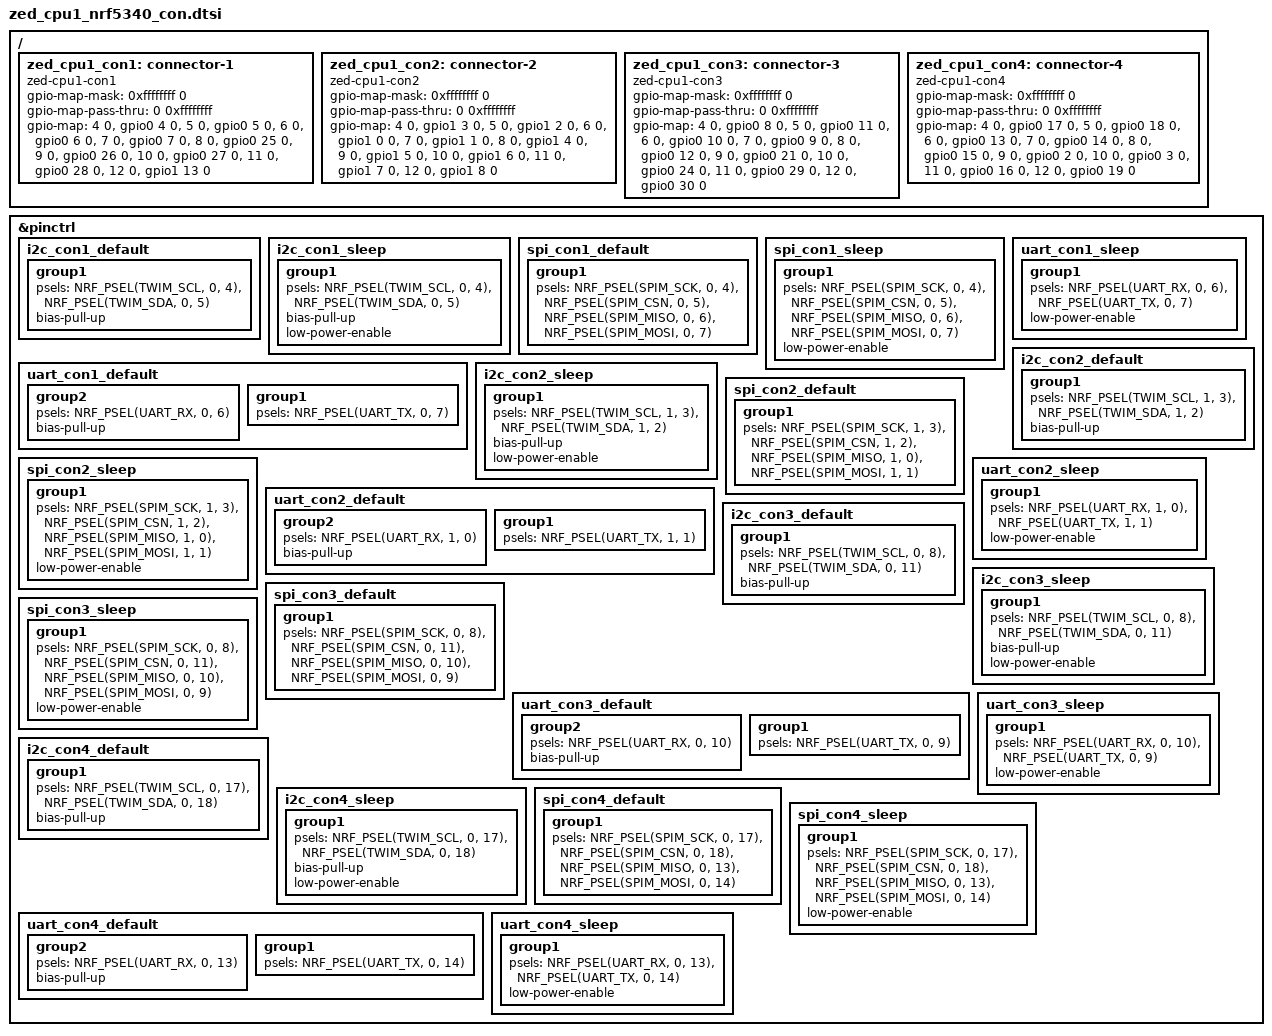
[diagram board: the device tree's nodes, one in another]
/*
 * Copyright (c) 2025 Lawrence King <lawrencek52@gmail.com>
 *
 * SPDX-License-Identifier: Apache-2.0
 */
/* TODO - add SPI to Con1 and con4 */
/*
 * the nrf5340 has many gpio pins, any of the pins on the connectors
 * can be used as GPIO, functions like I2C and PWM can be assigned
 * to any gpio. additionally the nrf5340 has some pins with special
 * features like QSPI, or ADC. These pins are located on the connectors
 * as shown below.
 */
/ {
	zed_cpu1_con1: connector-1 {
		compatible = "zed-cpu1-con1";
		#gpio-cells = <2>;
		gpio-map-mask = <0xffffffff 0>;
		gpio-map-pass-thru = <0 0xffffffff>;
		/* the connector has 12 pins,
			pin1 GND
			pin2 +3.3V
			pin3 Houskeeping ADC0
		  the remaining pins are connected to the nrf5340 */
		gpio-map = <4 0 &gpio0 4 0>,	/* SCL, AIN0, SPI_CLK P0.04 */
			   <5 0 &gpio0 5 0>,	/* SDA, AIN1, SPI_CS P0.05 */
			   <6 0 &gpio0 6 0>,	/* RXD, AIN2, SPI_MISO P0.06 */
			   <7 0 &gpio0 7 0>,	/* TXD, AIN3, SPI_MOSI P0.07 */
			   <8 0 &gpio0 25 0>,	/* AIN4 P0.25 */
			   <9 0 &gpio0 26 0>,	/* AIN5 P0.26 */
			   <10 0 &gpio0 27 0>,	/* AIN6 P0.27 */
			   <11 0 &gpio0 28 0>,	/* AIN7 P0.28 */
			   <12 0 &gpio1 13 0>;	/* P1.13 */
	};
};
&pinctrl {
	/omit-if-no-ref/i2c_con1_default: i2c_con1_default {
		group1 {
			psels = <NRF_PSEL(TWIM_SCL, 0, 4)>,
				<NRF_PSEL(TWIM_SDA, 0, 5)>;
			bias-pull-up;
			};
		};

	/omit-if-no-ref/i2c_con1_sleep: i2c_con1_sleep {
		group1 {
			psels = <NRF_PSEL(TWIM_SCL, 0, 4)>,
				 <NRF_PSEL(TWIM_SDA, 0, 5)>;
			bias-pull-up;
			low-power-enable;
		};
	};
	/omit-if-no-ref/spi_con1_default: spi_con1_default {
		group1 {
			psels = <NRF_PSEL(SPIM_SCK, 0, 4)>,
				<NRF_PSEL(SPIM_CSN, 0, 5)>,
				<NRF_PSEL(SPIM_MISO, 0, 6)>,
				<NRF_PSEL(SPIM_MOSI, 0, 7)>;
		};
	};

	/omit-if-no-ref/spi_con1_sleep: spi_con1_sleep {
		group1 {
			psels = <NRF_PSEL(SPIM_SCK, 0, 4)>,
				<NRF_PSEL(SPIM_CSN, 0, 5)>,
				<NRF_PSEL(SPIM_MISO, 0, 6)>,
				<NRF_PSEL(SPIM_MOSI, 0, 7)>;
			low-power-enable;
		};
	};
	/omit-if-no-ref/uart_con1_default: uart_con1_default {
		group2 {
			psels = <NRF_PSEL(UART_RX, 0, 6)>/*,
				<NRF_PSEL(UART_CTS, 0, 21)>*/;
			bias-pull-up;
		};
		group1 {
			psels = <NRF_PSEL(UART_TX, 0, 7)>/*,
				<NRF_PSEL(UART_RTS, 0, 19)>*/;
		};
	};
	/omit-if-no-ref/uart_con1_sleep: uart_con1_sleep {
		group1 {
			psels = <NRF_PSEL(UART_RX, 0, 6)>,
				<NRF_PSEL(UART_TX, 0, 7)>/*,
				<NRF_PSEL(UART_RTS, 0, 19)>,
				<NRF_PSEL(UART_CTS, 0, 21)> */;
			low-power-enable;
		};
	};
};


/ {
	zed_cpu1_con2: connector-2 {
		compatible = "zed-cpu1-con2";
		#gpio-cells = <2>;
		gpio-map-mask = <0xffffffff 0>;
		gpio-map-pass-thru = <0 0xffffffff>;
		/* the connector has 12 pins,
			pin1 GND
			pin2 +3.3V
			pin3 Houskeeping ADC1
		  the remaining pins are connected to the nrf5340 */
		gpio-map = <4 0 &gpio1 3 0>,	/* SCL, SPI_CLK P1.03 */
			   <5 0 &gpio1 2 0>,	/* SDA, SPI_CS P1.02 */
			   <6 0 &gpio1 0 0>,	/* RXD, SPI_MISO P1.00 */
			   <7 0 &gpio1 1 0>,	/* TXD, SPI_MOSI P1.01 */
			   <8 0 &gpio1 4 0>,	/* P1.04 */
			   <9 0 &gpio1 5 0>,	/* P1.05 */
			   <10 0 &gpio1 6 0>,	/* P1.06 */
			   <11 0 &gpio1 7 0>,	/* P1.07 */
			   <12 0 &gpio1 8 0>;	/* P1.08 */
	};
};
&pinctrl {
	/omit-if-no-ref/i2c_con2_default: i2c_con2_default {
		group1 {
			psels = <NRF_PSEL(TWIM_SCL, 1, 3)>,
				<NRF_PSEL(TWIM_SDA, 1, 2)>;
			bias-pull-up;
			};
		};

	/omit-if-no-ref/i2c_con2_sleep: i2c_con2_sleep {
		group1 {
			psels = <NRF_PSEL(TWIM_SCL, 1, 3)>,
				<NRF_PSEL(TWIM_SDA, 1, 2)>;
			bias-pull-up;
			low-power-enable;
		};
	};

	/omit-if-no-ref/spi_con2_default: spi_con2_default {
		group1 {
			psels = <NRF_PSEL(SPIM_SCK, 1, 3)>,
				<NRF_PSEL(SPIM_CSN, 1, 2)>,
				<NRF_PSEL(SPIM_MISO, 1, 0)>,
				<NRF_PSEL(SPIM_MOSI, 1, 1)>;
		};
	};

	/omit-if-no-ref/spi_con2_sleep: spi_con2_sleep {
		group1 {
			psels = <NRF_PSEL(SPIM_SCK, 1, 3)>,
				<NRF_PSEL(SPIM_CSN, 1, 2)>,
				<NRF_PSEL(SPIM_MISO, 1, 0)>,
				<NRF_PSEL(SPIM_MOSI, 1, 1)>;
			low-power-enable;
		};
	};
	/omit-if-no-ref/uart_con2_default: uart_con2_default {
		group2 {
			psels = <NRF_PSEL(UART_RX, 1, 0)>/*,
				<NRF_PSEL(UART_CTS, 0, 21)>*/;
			bias-pull-up;
		};
		group1 {
			psels = <NRF_PSEL(UART_TX, 1, 1)>/*,
				<NRF_PSEL(UART_RTS, 0, 19)>*/;
		};
	};
	/omit-if-no-ref/uart_con2_sleep: uart_con2_sleep {
		group1 {
			psels = <NRF_PSEL(UART_RX, 1, 0)>,
				<NRF_PSEL(UART_TX, 1, 1)>/*,
				<NRF_PSEL(UART_RTS, 0, 19)>,
				<NRF_PSEL(UART_CTS, 0, 21)> */;
			low-power-enable;
		};
	};
};


/ {
	zed_cpu1_con3: connector-3 {
		compatible = "zed-cpu1-con3";
		#gpio-cells = <2>;
		gpio-map-mask = <0xffffffff 0>;
		gpio-map-pass-thru = <0 0xffffffff>;
		/* the connector has 12 pins,
			pin1 GND
			pin2 +3.3V
			pin3 Houskeeping ADC2
		  the remaining pins are connected to the nrf5340 */
		gpio-map = <4 0 &gpio0 8 0>,	/* SCL SPI-SCK P0.08 */
			   <5 0 &gpio0 11 0>,	/* SDA SPI-CS P0.11 */
			   <6 0 &gpio0 10 0>,	/* RXD, SPI-MISO P0.10 */
			   <7 0 &gpio0 9 0>,	/* TXD, SPI-MOSI P0.09 */
			   <8 0 &gpio0 12 0>,	/* SPI-DCX P0.12 */
			   <9 0 &gpio0 21 0>,	/* P0.21 */
			   <10 0 &gpio0 24 0>,	/* P0.24 */
			   <11 0 &gpio0 29 0>,	/* P0.29 */
			   <12 0 &gpio0 30 0>;	/* P0.30 */
	};
};
&pinctrl {
	/omit-if-no-ref/i2c_con3_default: i2c_con3_default {
		group1 {
			psels = <NRF_PSEL(TWIM_SCL, 0, 8)>,
				<NRF_PSEL(TWIM_SDA, 0, 11)>;
				
			bias-pull-up;
			};
		};

	/omit-if-no-ref/i2c_con3_sleep: i2c_con3_sleep {
		group1 {
			psels = <NRF_PSEL(TWIM_SCL, 0, 8)>,
				 <NRF_PSEL(TWIM_SDA, 0, 11)>;
			bias-pull-up;
			low-power-enable;
		};
	};
	/omit-if-no-ref/spi_con3_default: spi_con3_default {
		group1 {
			psels = <NRF_PSEL(SPIM_SCK, 0, 8)>,
				<NRF_PSEL(SPIM_CSN, 0, 11)>,
				<NRF_PSEL(SPIM_MISO, 0, 10)>,
				<NRF_PSEL(SPIM_MOSI, 0, 9)>;
		};
	};

	/omit-if-no-ref/spi_con3_sleep: spi_con3_sleep {
		group1 {
			psels = <NRF_PSEL(SPIM_SCK, 0, 8)>,
				<NRF_PSEL(SPIM_CSN, 0, 11)>,
				<NRF_PSEL(SPIM_MISO, 0, 10)>,
				<NRF_PSEL(SPIM_MOSI, 0, 9)>;
			low-power-enable;
		};
	};
	/omit-if-no-ref/uart_con3_default: uart_con3_default {
		group2 {
			psels = <NRF_PSEL(UART_RX, 0, 10)>/*,
				<NRF_PSEL(UART_CTS, 0, 21)>*/;
			bias-pull-up;
		};
		group1 {
			psels = <NRF_PSEL(UART_TX, 0, 9)>/*,
				<NRF_PSEL(UART_RTS, 0, 19)>*/;
		};
	};
	/omit-if-no-ref/uart_con3_sleep: uart_con3_sleep {
		group1 {
			psels = <NRF_PSEL(UART_RX, 0, 10)>,
				<NRF_PSEL(UART_TX, 0, 9)>/*,
				<NRF_PSEL(UART_RTS, 0, 19)>,
				<NRF_PSEL(UART_CTS, 0, 21)> */;
			low-power-enable;
		};
	};
};


/ {
	zed_cpu1_con4: connector-4 {
		compatible = "zed-cpu1-con4";
		#gpio-cells = <2>;
		gpio-map-mask = <0xffffffff 0>;
		gpio-map-pass-thru = <0 0xffffffff>;
		/* the connector has 12 pins,
			pin1 GND
			pin2 +3.3V
			pin3 Houskeeping ADC2
		  the remaining pins are connected to the nrf5340 */
		gpio-map = <4 0 &gpio0 17 0>,	/* SCL QSPI-SCK P0.17 */
			   <5 0 &gpio0 18 0>,	/* SDA QSPI-CSN P0.18 */
			   <6 0 &gpio0 13 0>,	/* RXD, QSPI-IO0 P0.13 */
			   <7 0 &gpio0 14 0>,	/* TXD, QSPI-IO1 P0.14 */
			   <8 0 &gpio0 15 0>,	/* QSPI-IO2 P0.15 */
			   <9 0 &gpio0 2 0>,	/* NFC1 P0.02 */
			   <10 0 &gpio0 3 0>,	/* NFC2 P0.03 */
			   <11 0 &gpio0 16 0>,	/* QSPI-IO3 P0.16 */
			   <12 0 &gpio0 19 0>;	/* P0.19 */
	};
};
&pinctrl {
	/omit-if-no-ref/i2c_con4_default: i2c_con4_default {
		group1 {
			psels = <NRF_PSEL(TWIM_SCL, 0, 17)>,
				<NRF_PSEL(TWIM_SDA, 0, 18)>;
			bias-pull-up;
			};
		};

	/omit-if-no-ref/i2c_con4_sleep: i2c_con4_sleep {
		group1 {
			psels = <NRF_PSEL(TWIM_SCL, 0, 17)>,
				<NRF_PSEL(TWIM_SDA, 0, 18)>;
			bias-pull-up;
			low-power-enable;
		};
	};

	/omit-if-no-ref/spi_con4_default: spi_con4_default {
		group1 {
			psels = <NRF_PSEL(SPIM_SCK, 0, 17)>,
				<NRF_PSEL(SPIM_CSN, 0, 18)>,
				<NRF_PSEL(SPIM_MISO, 0, 13)>,
				<NRF_PSEL(SPIM_MOSI, 0, 14)>;
		};
	};
	/omit-if-no-ref/spi_con4_sleep: spi_con4_sleep {
		group1 {
			psels = <NRF_PSEL(SPIM_SCK, 0, 17)>,
				<NRF_PSEL(SPIM_CSN, 0, 18)>,
				<NRF_PSEL(SPIM_MISO, 0, 13)>,
				<NRF_PSEL(SPIM_MOSI, 0, 14)>;
			low-power-enable;
		};
	};

	/omit-if-no-ref/uart_con4_default: uart_con4_default {
		group2 {
			psels = <NRF_PSEL(UART_RX, 0, 13)>/*,
				<NRF_PSEL(UART_CTS, 0, 21)>*/;
			bias-pull-up;
		};
		group1 {
			psels = <NRF_PSEL(UART_TX, 0, 14)>/*,
				<NRF_PSEL(UART_RTS, 0, 19)>*/;
		};
	};
	/omit-if-no-ref/uart_con4_sleep: uart_con4_sleep {
		group1 {
			psels = <NRF_PSEL(UART_RX, 0, 13)>,
				<NRF_PSEL(UART_TX, 0, 14)>/*,
				<NRF_PSEL(UART_RTS, 0, 19)>,
				<NRF_PSEL(UART_CTS, 0, 21)> */;
			low-power-enable;
		};
	};
};

